# PIC32CM3204PL10020 register map
Vendor: Microchip Technology; Series: PIC32CMPL10; File version: 0
CPU: CM0+ r0p0, little endian, no MPU, no FPU, VTOR, 2 interrupt priority bits, 15 interrupts
Registers are 32-bit, read-write, reset 0x0 unless marked. A register's access mark holds for its fields unless they carry their own. Offsets are from the block's base; [hi:lo] are bit positions; {n}, {i} and the like mark numbered series; 'fields as' and 'values as' point back to an identical list.

## DMAC — Direct Memory Access Controller
Base 0x41006000
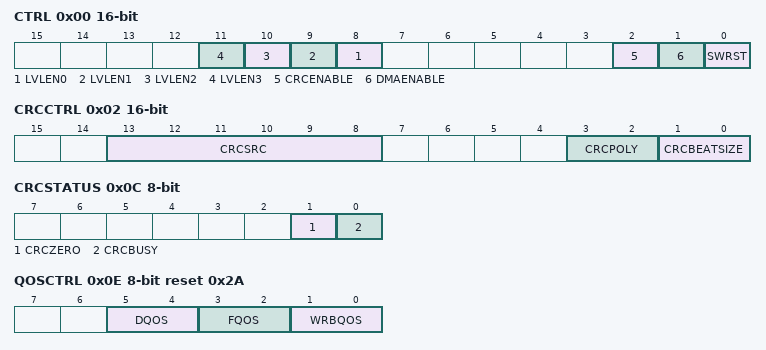
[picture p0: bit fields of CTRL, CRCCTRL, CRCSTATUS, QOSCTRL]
0x00 CTRL 16-bit — Control
  [n+8] LVLEN{n} (n=0..3) — Priority Level {n} Enable
  [2] CRCENABLE
  [1] DMAENABLE
  [0] SWRST — Software Reset
0x02 CRCCTRL 16-bit — CRC Control
  [13:8] CRCSRC — CRC Input Source
    0=NOACT (No action); 1=IO (I/O interface); 32=CHN0 (DMA Channel 0); 33=CHN1 (DMA Channel 1)
  [3:2] CRCPOLY — CRC Polynomial Type
    0=CRC16 (CRC-16 (CRC-CCITT)); 1=CRC32 (CRC32 (IEEE 802.3))
  [1:0] CRCBEATSIZE
    0=BYTE (8-bit bus transfer); 1=HWORD (16-bit bus transfer); 2=WORD (32-bit bus transfer)
0x04 CRCDATAIN — CRC Data Input
0x08 CRCCHKSUM — CRC Checksum
0x0C CRCSTATUS 8-bit
  [1] CRCZERO
  [0] CRCBUSY — CRC Module Busy
0x0D DBGCTRL 8-bit — Debug Control
  [0] DBGRUN — Debug Run
0x0E QOSCTRL 8-bit reset 0x2A — Quality of Service Control
  [all] fields
    0=DISABLE (Background (no sensitive operation)); 1=LOW (Sensitive Bandwidth); 2=MEDIUM (Sensitive Latency); 3=HIGH (Critical Latency)
  [5:4] DQOS — Data Transfer Quality of Service
  [3:2] FQOS — Fetch Quality of Service
  [1:0] WRBQOS — Write-Back Quality of Service
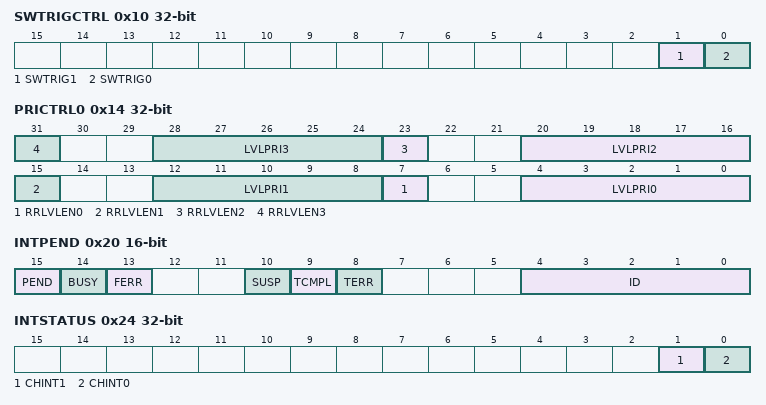
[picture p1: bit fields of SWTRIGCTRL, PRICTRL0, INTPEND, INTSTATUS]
0x10 SWTRIGCTRL — Software Trigger Control
  [1] SWTRIG1 — Channel 1 Software Trigger
  [0] SWTRIG0 — Channel 0 Software Trigger
0x14 PRICTRL0 — Priority Control 0
  [8n+7] RRLVLEN{n} (n=0..3) — Level {n} Round-Robin Arbitration Enable
  [8n+4:8n] LVLPRI{n} (n=0..3) — Level {n} Channel Priority Number
    0=CHN0 (DMA Channel 0); 1=CHN1 (DMA Channel 1)
0x20 INTPEND 16-bit — Interrupt Pending
  [15] PEND — Pending
  [14] BUSY
  [13] FERR — Fetch Error
  [10] SUSP — Channel Suspend
  [9] TCMPL — Transfer Complete
  [8] TERR — Transfer Error
  [4:0] ID — Channel ID
    0=CHN0 (DMA Channel 0); 1=CHN1 (DMA Channel 1)
0x24 INTSTATUS ro — Interrupt Status
  [1] CHINT1 — Channel 1 Pending Interrupt
  [0] CHINT0 — Channel 0 Pending Interrupt
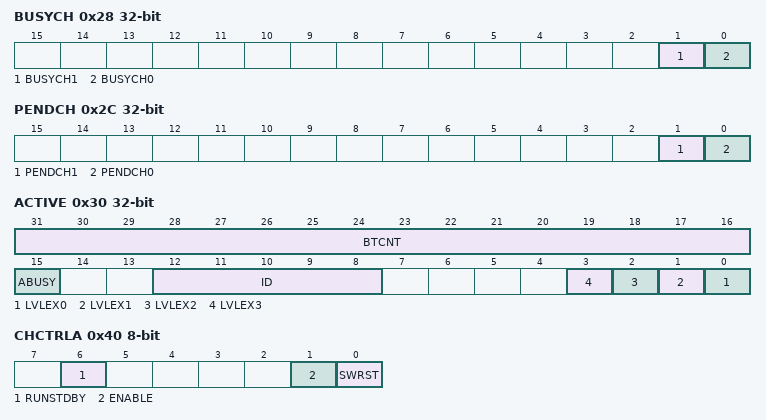
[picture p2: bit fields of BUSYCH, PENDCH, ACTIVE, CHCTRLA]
0x28 BUSYCH ro — Busy Channels
  [1] BUSYCH1 — Busy Channel 1
  [0] BUSYCH0 — Busy Channel 0
0x2C PENDCH ro — Pending Channels
  [1] PENDCH1 — Pending Channel 1
  [0] PENDCH0 — Pending Channel 0
0x30 ACTIVE ro — Active Channel and Levels
  [31:16] BTCNT — Active Channel Block Transfer Count
  [15] ABUSY — Active Channel Busy
  [12:8] ID — Active Channel ID
    0=CHN0 (DMA Channel 0); 1=CHN1 (DMA Channel 1)
  [n] LVLEX{n} (n=0..3) — Level {n} Channel Trigger Request Executing
0x34 BASEADDR — Descriptor Memory Section Base Address
  [31:0] BASEADDR — Descriptor Memory Base Address
0x38 WRBADDR — Write-Back Memory Section Base Address
  [31:0] WRBADDR — Write-Back Memory Base Address
0x3F CHID 8-bit — Channel ID
  [4:0] ID
    0=CHN0 (DMA Channel 0); 1=CHN1 (DMA Channel 1)
0x40 CHCTRLA 8-bit — Channel Control A
  [6] RUNSTDBY — Channel run in standby
  [1] ENABLE — Channel Enable
  [0] SWRST — Channel Software Reset
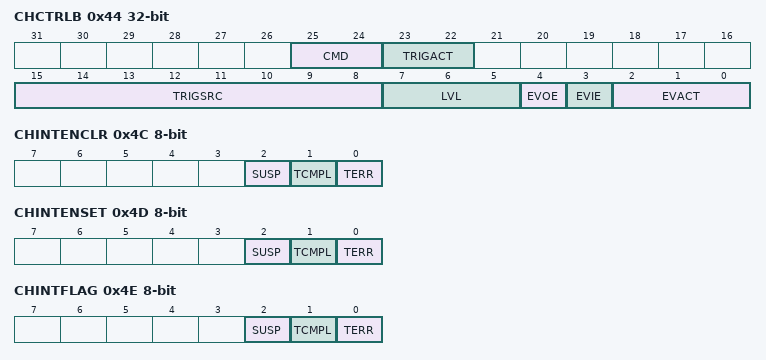
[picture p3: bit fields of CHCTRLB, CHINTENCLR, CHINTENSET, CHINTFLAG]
0x44 CHCTRLB — Channel Control B
  [25:24] CMD — Software Command
    0=NOACT (No action); 1=SUSPEND (Channel suspend operation); 2=RESUME (Channel resume operation)
  [23:22] TRIGACT — Trigger Action
    0=BLOCK (One trigger required for each block transfer); 2=BEAT (One trigger required for each beat transfer); 3=TRANSACTION (One trigger required for each transaction)
  [15:8] TRIGSRC — Trigger Source
    0=DISABLE (Only software/event triggers); 1=SERCOM0_RX (SERCOM0 RX Trigger); 2=SERCOM0_TX (SERCOM0 TX Trigger); 3=SERCOM1_RX (SERCOM1 RX Trigger); 4=SERCOM1_TX (SERCOM1 TX Trigger); 5=TC0_OVF (TC0 Overflow Trigger); 6=TC0_MC0 (TC0 Match/Compare 0 Trigger); 7=TC0_MC1 (TC0 Match/Compare 1 Trigger); 8=TC1_OVF (TC1 Overflow Trigger); 9=TC1_MC0 (TC1 Match/Compare 0 Trigger); 10=TC1_MC1 (TC1 Match/Compare 1 Trigger); 11=TC2_OVF (TC2 Overflow Trigger); 12=TC2_MC0 (TC2 Match/Compare 0 Trigger); 13=TC2_MC1 (TC2 Match/Compare 1 Trigger); 14=TCC0_OVF (TCC0 Overflow Trigger); {v}=TCC0_MC{v-15} (TCC0 Match/Compare {v-15} Trigger) (v=15..18); 19=ADC0_RESRDY (ADC0 Restult Ready Trigger); 20=ADC0_SAMPRDY (ADC0 Sample Ready Trigger); 21=DSU_DCC0 (DSU Debug Communication Channel 0); 22=DSU_DCC1 (DSU Debug Communication Channel 1)
  [7:5] LVL — Channel Arbitration Level
    {v}=Channel priority level {v} (v=0..3)
  [4] EVOE — Channel Event Output Enable
  [3] EVIE — Channel Event Input Enable
  [2:0] EVACT — Event Input Action
    0=NOACT (No action); 1=TRIG (Normal transfer and conditional transfer on strobe trigger); 2=CTRIG (Conditional transfer trigger); 3=CBLOCK (Conditional block transfer); 4=SUSPEND (Channel suspend operation); 5=RESUME (Channel resume operation); 6=SSKIP (Skip next block suspend action)
0x4C CHINTENCLR 8-bit write-1-clears — Channel Interrupt Enable Clear
  [2] SUSP — Suspend Interrupt Enable
  [1] TCMPL — Transfer Complete Interrupt Enable
  [0] TERR — Transfer Error Interrupt Enable
0x4D CHINTENSET 8-bit write-1-sets — Channel Interrupt Enable Set
  fields as CHINTENCLR
0x4E CHINTFLAG 8-bit write-1-clears — Channel Interrupt Flag Status and Clear
  [2] SUSP — Suspend
  [1] TCMPL — Transfer Complete
  [0] TERR — Transfer Error
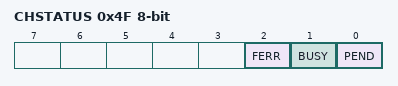
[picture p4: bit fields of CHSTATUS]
0x4F CHSTATUS 8-bit ro — Channel Status
  [2] FERR — Fetch Error
  [1] BUSY
  [0] PEND — Pending

## Notices in the file
Copyright (c) 2026 Microchip Technology Inc.
SPDX-License-Identifier: Apache-2.0
Licensed under the Apache License, Version 2.0 (the "License");
you may not use this file except in compliance with the License.
You may obtain a copy of the License at
http://www.apache.org/licenses/LICENSE-2.0
Unless required by applicable law or agreed to in writing, software
distributed under the License is distributed on an "AS IS" BASIS,
WITHOUT WARRANTIES OR CONDITIONS OF ANY KIND, either express or implied.
See the License for the specific language governing permissions and
limitations under the License.
